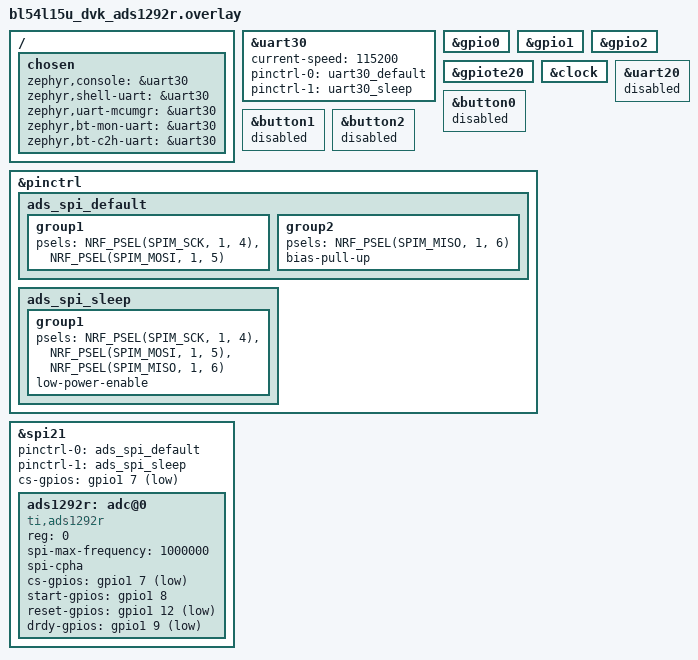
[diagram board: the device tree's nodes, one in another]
#include <zephyr/dt-bindings/gpio/gpio.h>
#include <zephyr/dt-bindings/pinctrl/nrf-pinctrl.h>

/*
 * ADS1292R wiring for the Ezurio BL54L15u DVK / 453-00223-K1.
 *
 * This overlay keeps the application driver unchanged and only describes the
 * board-specific pins.  It uses the DVK's mikroBUS-style header names:
 *
 *   ADS SCK        -> P1.04
 *   ADS DIN/MOSI   -> P1.05
 *   ADS DOUT/MISO  -> P1.06
 *   ADS CS         -> P1.07
 *   ADS DRDY       -> GPIO / P1.12
 *   ADS PWDN/RESET -> P1.13
 *   ADS START      -> MB_TX / P1.09
 *
 * These SPI pins match the audio SD bring-up wiring so the ADS can be tested
 * on a header path already proven to work electrically.
 */


/ {
    chosen {
        zephyr,console = &uart30;
        zephyr,shell-uart = &uart30;
        zephyr,uart-mcumgr = &uart30;
        zephyr,bt-mon-uart = &uart30;
        zephyr,bt-c2h-uart = &uart30;
    };
};

&uart30 {
    status = "okay";
    current-speed = <115200>;
    pinctrl-0 = <&uart30_default>;
    pinctrl-1 = <&uart30_sleep>;
    pinctrl-names = "default", "sleep";
};
&gpio0 { status = "okay"; };
&gpio1 { status = "okay"; };
&gpio2 { status = "okay"; };
&gpiote20 { status = "okay"; };
&clock { status = "okay"; };

&uart20 {
    status = "disabled";
};

/* These default DVK functions use GPIOs selected above. */
&button0 { status = "disabled"; };  /* P1.13 / ADS /PWDN */
&button1 { status = "disabled"; };  /* P1.09 / MB_TX / ADS START */
&button2 { status = "disabled"; };  /* P1.08 / MB_RX, left unused for ADS */

&pinctrl {
    ads_spi_default: ads_spi_default {
        group1 {
            psels = <NRF_PSEL(SPIM_SCK, 1, 4)>,
                    <NRF_PSEL(SPIM_MOSI, 1, 5)>;
        };
        group2 {
            psels = <NRF_PSEL(SPIM_MISO, 1, 6)>;
            bias-pull-up;
        };
    };

    ads_spi_sleep: ads_spi_sleep {
        group1 {
            psels = <NRF_PSEL(SPIM_SCK, 1, 4)>,
                    <NRF_PSEL(SPIM_MOSI, 1, 5)>,
                    <NRF_PSEL(SPIM_MISO, 1, 6)>;
            low-power-enable;
        };
    };
};

&spi21 {
    status = "okay";
    pinctrl-0 = <&ads_spi_default>;
    pinctrl-1 = <&ads_spi_sleep>;
    pinctrl-names = "default", "sleep";
    cs-gpios = <&gpio1 7 GPIO_ACTIVE_LOW>;

    ads1292r: adc@0 {
        compatible = "ti,ads1292r";
        reg = <0>;
        spi-max-frequency = <1000000>;
        spi-cpha;
        cs-gpios = <&gpio1 7 GPIO_ACTIVE_LOW>;
        start-gpios = <&gpio1 8 GPIO_ACTIVE_HIGH>;
        reset-gpios = <&gpio1 12 GPIO_ACTIVE_LOW>;
        drdy-gpios = <&gpio1 9 GPIO_ACTIVE_LOW>;
    };
};







